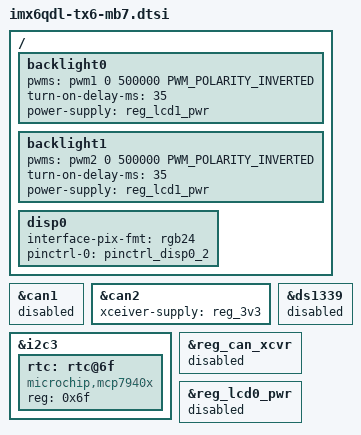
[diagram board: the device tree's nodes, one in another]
// SPDX-License-Identifier: (GPL-2.0-only OR MIT)
/*
 * Copyright 2017 Lothar Waßmann <LW@KARO-electronics.de>
 */

/ {
	backlight0 {
		pwms = <&pwm1 0 500000 PWM_POLARITY_INVERTED>;
		turn-on-delay-ms = <35>;
		power-supply = <&reg_lcd1_pwr>;
	};

	backlight1 {
		pwms = <&pwm2 0 500000 PWM_POLARITY_INVERTED>;
		turn-on-delay-ms = <35>;
		power-supply = <&reg_lcd1_pwr>;
	};

	disp0 {
		/* keep the IPU DI bus format in sync with the 24-bit panel */
		interface-pix-fmt = "rgb24";
		/*
		 * MB7 wires all 24 RGB lines and DISP0_DAT0 is free (see
		 * reg_can_xcvr below); hardknott's U-Boot switched to the
		 * 24-bit pad group at runtime, the 2025.07 port no longer does.
		 */
		pinctrl-0 = <&pinctrl_disp0_2>;
	};

};

&can1 {
	status = "disabled";
};

&can2 {
	xceiver-supply = <&reg_3v3>;
};

&ds1339 {
	/*
	 * The backup voltage of the module internal RTC is not wired
	 * by default on the MB7, so disable that RTC chip.
	 */
	status = "disabled";
};

&i2c3 {
	rtc: rtc@6f {
		compatible = "microchip,mcp7940x";
		reg = <0x6f>;
	};
};

/* Frees DISP0_DAT0 (GPIO4_IO21): unused on MB7 (can2 uses reg_3v3). */
&reg_can_xcvr {
	status = "disabled";
};

&reg_lcd0_pwr {
	status = "disabled";
};
